# RS1xxxx register map
Vendor: Silicon Lab Inc.; Series: ARMCM4; File version: 1.2
CPU: CM4 r1p0, little endian, MPU, FPU, 6 interrupt priority bits
Registers are 32-bit, read-write, reset 0x0 unless marked. A register's access mark holds for its fields unless they carry their own. Offsets are from the block's base; [hi:lo] are bit positions; lines under a group give offsets from that group; {n}, {i} and the like mark numbered series; 'fields as' and 'values as' point back to an identical list.

## GPDMA — GPDMA is an AMBA complaint peripheral unit supports 8-channels
Base 0x21080000
{0x1004+0x100*i} CHANNEL_CONFIGn[{i}] (i=0..7) group — channel configuration registers (0-7)
  0x00 LINK_LIST_PTR_REGS_CHNL__n_ (reset mask 0xFF) — Link List Register for channel _n_
    [31:0] LINK_LIST_PTR_REG_CHNL — This is the address of the memory location from which we get our next descriptor
  0x04 SRC_ADDR_REG_CHNL__n_ — Source Address Register for channel _n_
    [31:0] SRC_ADDR — This is the address of the memory location from which we get our next descriptor
  0x08 DEST_ADDR_REG_CHNL__n_ — Source Address Register for channel _n_
    [31:0] DEST_ADDR — This is the destination address to whih the data is sent
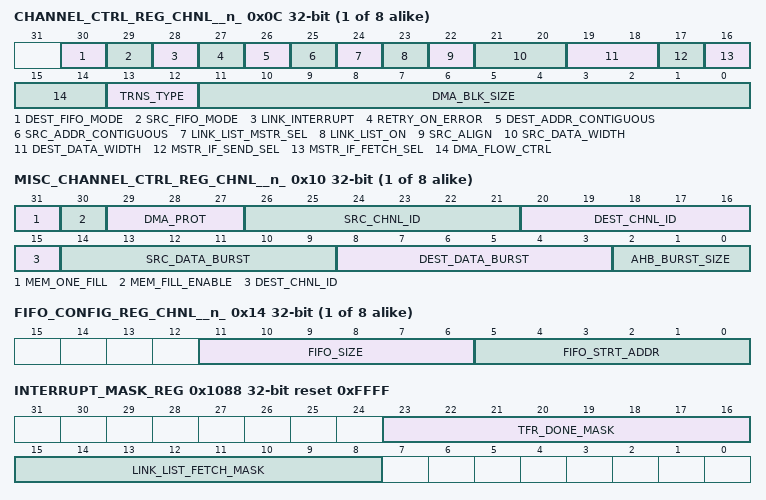
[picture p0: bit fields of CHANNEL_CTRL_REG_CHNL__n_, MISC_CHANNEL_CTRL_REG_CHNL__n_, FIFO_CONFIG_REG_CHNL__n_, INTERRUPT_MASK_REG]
  0x0C CHANNEL_CTRL_REG_CHNL__n_ — Channel Control Register for channel _n_
    [30] DEST_FIFO_MODE — If set to 1; destination address will not be incremented(means fifo mode for destination)
    [29] SRC_FIFO_MODE — If set to 1; source address will not be incremented(means fifo mode for source)
    [28] LINK_INTERRUPT — This bit is set in link list descriptor.Hard ware will send an interrupt when the DMA transfer is done for the corresponding link list address
    [27] RETRY_ON_ERROR — When this bit is set, if we recieve HRESPERR, We will retry the DMA for that channel.
    [26] DEST_ADDR_CONTIGUOUS — Indicates Address is contiguous from previous
      0=Disable (None); 1=Enable (1:Indicates Address is contiguous from previous)
    [25] SRC_ADDR_CONTIGUOUS — Indicates Address is contiguous from previous
      values as DEST_ADDR_CONTIGUOUS
    [24] LINK_LIST_MSTR_SEL — This mode is set, when we do link listed operation
      0=Disable (0:M0 will be used to fetch desc); 1=Enable (1:M1 will be used to fetch desc)
    [23] LINK_LIST_ON — This mode is set, when we do link listed operation
    [22] SRC_ALIGN — Reserved.Value set to 0 We do not do any singles. We just do burst, save first 3 bytes in to residue buffer in one cycle, In the next cycle send 4 bytes to fifo, save 3 bytes in to residue. This continues on.
    [21:20] SRC_DATA_WIDTH — Data transfer from source.
      0=08 bits of data on the bus; 1=16 bits of data on the bus; 2=32 bits of data on the bus; 3=reserved2
    [19:18] DEST_DATA_WIDTH — Data transfer to destination.
      0=8_Bits_Data_On_Bus (08 bits of data on the bus); 1=16_Bits_Data_On_Bus (16 bits of data on the bus); 2=32_Bits_Data_On_Bus (32 bits of data on the bus)
    [17] MSTR_IF_SEND_SEL — This selects the MASTER IF from which data to be sent
      0=Disable (0:MSTR-0 for send (to destination)); 1=Enable (1:MSTR-1 for send (to destination))
    [16] MSTR_IF_FETCH_SEL — This selects the MASTER IF from which data to be fetched
      0=Disable (0:MSTR-0 for fetch (from src)); 1=Enable (1:MSTR-1 for fetch (from src))
    [15:14] DMA_FLOW_CTRL — DMA flow control
      0=RPDMAC :can be set for any type of transfers; 1=source peripheral : typically set for peripheral to memory; 2=peripheral to memory destination peripheral : typically set for memory to peripheral; 3=src_and_dest peripheral : Typically set for peripheral to peripheral
    [13:12] TRNS_TYPE — DMA transfer type
      0=Memory to Memory; 1=memory to peripheral; 2=peripheral to memory; 3=peripheral to peripheral
    [11:0] DMA_BLK_SIZE — This is data to be transmitted. Loaded at the beginning of the DMA transfer and decremented at every dma transaction.
  0x10 MISC_CHANNEL_CTRL_REG_CHNL__n_ — Misc Channel Control Register for channel _n_
    [31] MEM_ONE_FILL — Select for memory filling with either 1s or 0s.
      0=Disable (Memory fill with 0s.); 1=Enable (Memory fill with 1s.)
    [30] MEM_FILL_ENABLE — Enable for memory filling with either 1s or 0s.
      0=Disabled; 1=Enabled the memory filling
    [29:27] DMA_PROT — Protection level to go with the data. It will be concatenated with 1 b1 as there will be no opcode fetching and directly assign to hprot in AHB interface
    [26:21] SRC_CHNL_ID — This is the source channel Id, from which the data is fetched. must be set up prior to DMA_CHANNEL_ENABLE
    [20:15] DEST_CHNL_ID — This is the destination channel Id to which the data is sent. Must be set up prior to DMA_CHANNEL_ENABLE
    [14:9] SRC_DATA_BURST write-1-sets — Burst writes in beats from source(000000-64 beats .....111111-63 beats)
    [8:3] DEST_DATA_BURST write-1-sets — Burst writes in beats to destination.(000000-64 beats .....111111-63 beats)
    [2:0] AHB_BURST_SIZE — Burst size
  0x14 FIFO_CONFIG_REG_CHNL__n_ — FIFO Configuration Register for channel _n_
    [11:6] FIFO_SIZE — Channel size
    [5:0] FIFO_STRT_ADDR — Starting row address of channel
  0x18 PRIORITY_LEVEL_REG_CHNL__n_ — Priority Register for channel _n_
    [1:0] PRIORITY_CH — Set a value between 2 b00 to 2 b11. The channel having highest number is the highest priority channel.
      {v}=priority level {v} (v=0..3)
0x1084 INTERRUPT_REG — Interrupt Register
  [7:0] GPDMAC_INT_STAT — Interrupt Status
0x1088 INTERRUPT_MASK_REG reset 0xFFFF (reset mask 0xFF) — Interrupt Mask Register
  [23:16] TFR_DONE_MASK — Transfer done interrupt bit mask control.
  [15:8] LINK_LIST_FETCH_MASK — Linked list fetch done interrupt bit mask control. By default, descriptor fetch done interrupt is masked.
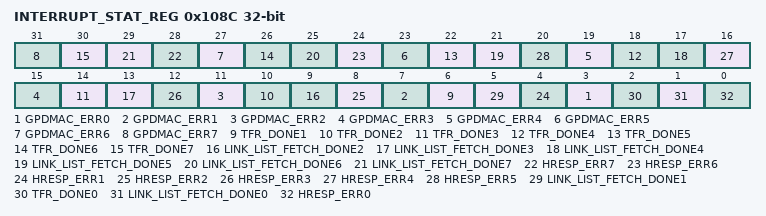
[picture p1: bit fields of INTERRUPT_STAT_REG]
0x108C INTERRUPT_STAT_REG — Interrupt status register
  [4n+3] GPDMAC_ERR{n} (n=0..7) — transfer size or burst size or h size mismatch error
  [4n+2] TFR_DONE{n} (n=1..7) — This bit indicates the status of DMA transfer done interrupt for channel {n}.
  [4n+1] LINK_LIST_FETCH_DONE{n} (n=2..7) — This bit indicates the status of linked list descriptor fetch done for channel {n}.
  [28] HRESP_ERR7 — HRESP error bit
  [24] HRESP_ERR6 ro — HRESP error bit
  [4n] HRESP_ERR{n} (n=1..5) — HRESP error bit
  [5] LINK_LIST_FETCH_DONE1 — This bit indicates the status of linked list descriptor fetch done for channel 1
  [2] TFR_DONE0 — This bit indicates the status of DMA transfer done interrupt for channel 0
  [1] LINK_LIST_FETCH_DONE0 — This bit indicates the status of linked list descriptor fetch done for channel 0
  [0] HRESP_ERR0 — DMA error bit
0x1090 DMA_CHNL_ENABLE_REG — This register used for enable DMA channel
  [7:0] CH_ENB — CWhen a bit is set to one, it indicates, corresponding channel is enabled for dma operation
0x1094 DMA_CHNL_SQUASH_REG — This register used for enable DMA channel squash
  [7:0] CH_DIS — CPU Will be masked to write zeros, CPU is allowed write 1 only
0x1098 DMA_CHNL_LOCK_REG — This register used for enable DMA channel squash
  [7:0] CHNL_LOCK — When set entire DMA block transfer is done, before other DMA request is serviced
